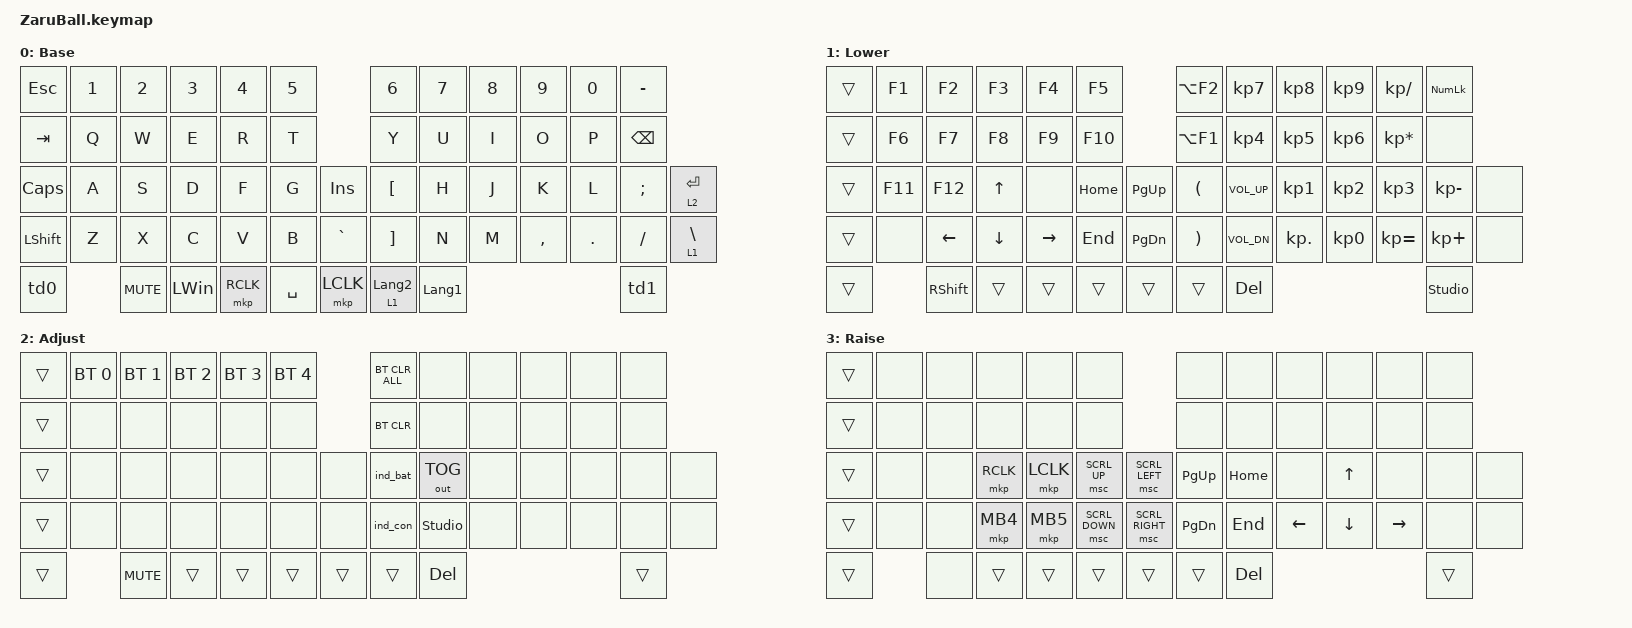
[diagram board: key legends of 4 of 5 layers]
#include <behaviors/rgbled_widget.dtsi>
#include <input/processors.dtsi>
#include <dt-bindings/zmk/input_transform.h>
#include <behaviors.dtsi>
#include <dt-bindings/zmk/bt.h>
#include <dt-bindings/zmk/keys.h>
#include <dt-bindings/zmk/outputs.h>
#include <dt-bindings/zmk/pointing.h>

#define BASE 0
#define LOWER 1
#define RAISE 2
#define ADJUST 3
#define MOUSE 4
#define SCROLL 1
#define JP_DQUOTE       AT                // "
#define JP_AMPERSAND    CARET             // &
#define JP_QUOTE        AMPERSAND         // '
#define JP_EQUAL        UNDER             // =
#define JP_CARET        EQUAL             // ^
#define JP_YEN          0x89              // ¥
#define JP_PLUS         COLON             // +
#define JP_TILDE        PLUS              // ~
#define JP_PIPE         LS(0x89)          // |
#define JP_AT           LEFT_BRACKET      // @
#define JP_COLON        SINGLE_QUOTE      // :
#define JP_ASTERISK     DOUBLE_QUOTES     // *
#define JP_BACKQUOTE    LEFT_BRACE        // `
#define JP_UNDERSCORE   LS(0x87)          // _
#define JP_LBRACKET     RIGHT_BRACKET     // [
#define JP_RBRACKET     BACKSLASH         // ]
#define JP_LPAREN       ASTERISK          // (
#define JP_RPAREN       LEFT_PARENTHESIS  // )
#define JP_LBRACE       RIGHT_BRACE       // {
#define JP_RBRACE       PIPE              // }
#define JP_KANA         LANGUAGE_1        // かな
#define JP_EISU         LANGUAGE_2        // 英数
#define JP_HANZEN       GRAVE             // 半角/全角
#define JP_BSLH  INT1         // (backslash)

// スクロール量の設定

#define ZMK_POINTING_DEFAULT_SCRL_VAL 100

// トラックボールの設定(AML, SCROLL)

&trackball_listener {
    input-processors = <
                        // トラックボールの向きの変更(ZaruBallv1とv2,v3ではセンサーの向きが異なるので調整してください。デフォルトではv2,v3用)
                         &zip_xy_transform (INPUT_TRANSFORM_XY_SWAP | INPUT_TRANSFORM_Y_INVERT | INPUT_TRANSFORM_X_INVERT)
                         &zip_temp_layer MOUSE 500 // 500ms stay at mouse layer
    >;

    scroller {
        layers = <SCROLL>;
        input-processors = <
                            // スクロールの向きの変更
                            &zip_xy_transform (INPUT_TRANSFORM_XY_SWAP | INPUT_TRANSFORM_X_INVERT)
                            &zip_xy_scaler 1 20 // スクロールの感度(default: x20)
                            &zip_xy_to_scroll_mapper
        >;
    };
};

/ {
    conditional_layers {
        compatible = "zmk,conditional-layers";

        tri_layer {
            if-layers = <1 3>;
            then-layer = <2>;
        };
    };
};

/ {
    behaviors {
        // スクロール用のbehaviorの設定

        scroll_down_up: behavior_sensor_rotate_mouse_wheel_down_up {
            compatible = "zmk,behavior-sensor-rotate";
            #sensor-binding-cells = <0>;
            bindings = <&msc SCRL_DOWN>, <&msc SCRL_UP>;

            tap-ms = <20>; // スクロールのタップ時間
        };

        td0: tap_dance_0 {
            compatible = "zmk,behavior-tap-dance";
            #binding-cells = <0>;
            tapping-term-ms = <200>;
            bindings = <&mt LALT LANG2>, <&mo 3>, <&mo 4>;
        };

        td1: tap_dance_1 {
            compatible = "zmk,behavior-tap-dance";
            #binding-cells = <0>;
            tapping-term-ms = <200>;
            bindings = <&mt RCTL LANG1>, <&mo 3>, <&mo 5>;
        };
    };
};

&sl { release-after-ms = <250>; }; // time needed for double click (for mkp_exit_AML)
/ {
    macros {
        // When in AML, move to default layer when key (except mouse button) pressed

        to_layer_0: to_layer_0 {
            compatible = "zmk,behavior-macro-one-param";
            #binding-cells = <1>;
            bindings = <&to 0 &macro_param_1to1 &kp MACRO_PLACEHOLDER>;
            label = "TO_layer_0";
        };

        // When LCLK pressed, exit AML (after 250ms cause by sticky layer)

        mkp_exit_AML: mkp_exit_AML {
            compatible = "zmk,behavior-macro-one-param";
            #binding-cells = <1>;
            bindings =
                <&macro_press>,
                <&macro_param_1to1 &mkp MACRO_PLACEHOLDER>,
                <&macro_pause_for_release>,
                <&macro_release>,
                <&macro_param_1to1 &mkp MACRO_PLACEHOLDER>,
                <&macro_tap>,
                <&sl 4>;

            label = "MKP_EXIT_AML";
        };

        // Support swapping into Scroll layer when AML is activated

        to_scroll_layer: to_scroll_layer {
            compatible = "zmk,behavior-macro";
            #binding-cells = <0>;
            bindings =
                <&to 1>,
                <&macro_press>,
                <&mo 1>,
                <&macro_pause_for_release>,
                <&macro_release>,
                <&mo 1>;
        };
    };
};

/ {
    keymap {
        compatible = "zmk,keymap";

        base_layer {
            display-name = "Base";
            sensor-bindings = <&scroll_down_up>;
            bindings = <
&kp ESC    &kp N1  &kp N2      &kp N3    &kp N4     &kp N5                &kp NUMBER_6      &kp N7          &kp N8  &kp N9     &kp N0   &kp MINUS
&kp TAB    &kp Q   &kp W       &kp E     &kp R      &kp T                 &kp Y             &kp U           &kp I   &kp O      &kp P    &kp BACKSPACE
&kp CAPS   &kp A   &kp S       &kp D     &kp F      &kp G      &kp INS    &kp LBKT          &kp H           &kp J   &kp K      &kp L    &kp SEMI       &lt 2 ENTER
&kp LSHFT  &kp Z   &kp X       &kp C     &kp V      &kp B      &kp GRAVE  &kp RBKT          &kp N           &kp M   &kp COMMA  &kp DOT  &kp FSLH       &lt 1 BACKSLASH
&td0               &kp C_MUTE  &kp LWIN  &mkp RCLK  &kp SPACE  &mkp LCLK  &lt 1 LANGUAGE_2  &kp LANGUAGE_1                              &td1
            >;
        };

        lower_layer {
            display-name = "Lower";
            sensor-bindings = <&inc_dec_kp RIGHT LEFT>;
            bindings = <
&trans  &kp F1   &kp F2     &kp F3    &kp F4     &kp F5               &kp LA(F2)  &kp KP_N7     &kp KP_N8   &kp KP_N9  &kp KP_SLASH     &kp KP_NUMLOCK
&trans  &kp F6   &kp F7     &kp F8    &kp F9     &kp F10              &kp LA(F1)  &kp KP_N4     &kp KP_N5   &kp KP_N6  &kp KP_MULTIPLY  &none
&trans  &kp F11  &kp F12    &kp UP    &none      &kp HOME  &kp PG_UP  &kp LPAR    &kp C_VOL_UP  &kp KP_N1   &kp KP_N2  &kp KP_N3        &kp KP_MINUS    &none
&trans  &none    &kp LEFT   &kp DOWN  &kp RIGHT  &kp END   &kp PG_DN  &kp RPAR    &kp C_VOL_DN  &kp KP_DOT  &kp KP_N0  &kp KP_EQUAL     &kp KP_PLUS     &none
&trans           &kp RSHFT  &trans    &trans     &trans    &trans     &trans      &kp DEL                                               &studio_unlock
            >;
        };

        adjust_layer {
            display-name = "Adjust";
            sensor-bindings = <&inc_dec_kp C_VOL_UP C_VOL_DN>;
            bindings = <
&trans  &bt BT_SEL 0  &bt BT_SEL 1  &bt BT_SEL 2  &bt BT_SEL 3  &bt BT_SEL 4          &bt BT_CLR_ALL  &none           &none  &none  &none  &none
&trans  &none         &none         &none         &none         &none                 &bt BT_CLR      &none           &none  &none  &none  &none
&trans  &none         &none         &none         &none         &none         &none   &ind_bat        &out OUT_TOG    &none  &none  &none  &none   &none
&trans  &none         &none         &none         &none         &none         &none   &ind_con        &studio_unlock  &none  &none  &none  &none   &none
&trans                &kp C_MUTE    &trans        &trans        &trans        &trans  &trans          &kp DEL                              &trans
            >;
        };

        raise_layer {
            display-name = "Raise";
            sensor-bindings = <&inc_dec_kp LA(F2) LA(F1)>;
            bindings = <
&trans  &none  &none  &none      &none      &none                            &none      &none     &none     &none     &none      &none
&trans  &none  &none  &none      &none      &none                            &none      &none     &none     &none     &none      &none
&trans  &none  &none  &mkp RCLK  &mkp LCLK  &msc SCRL_UP    &msc SCRL_LEFT   &kp PG_UP  &kp HOME  &none     &kp UP    &none      &none   &none
&trans  &none  &none  &mkp MB4   &mkp MB5   &msc SCRL_DOWN  &msc SCRL_RIGHT  &kp PG_DN  &kp END   &kp LEFT  &kp DOWN  &kp RIGHT  &none   &none
&trans         &none  &trans     &trans     &trans          &trans           &trans     &kp DEL                                  &trans
            >;
        };

        mouse_layer {
            display-name = "Mouse";
            sensor-bindings = <&scroll_down_up>;
            bindings = <
&to_layer_0 ESC             &to_layer_0 N1  &to_layer_0 N2  &to_layer_0 N3  &to_layer_0 N4      &to_layer_0 N5                   &to_layer_0 N6   &to_layer_0 N7  &to_layer_0 N8  &to_layer_0 N9  &to_layer_0 N0      &to_layer_0 MINUS
&to_layer_0 TAB             &to_layer_0 Q   &to_layer_0 W   &to_layer_0 E   &to_layer_0 R       &to_layer_0 T                    &to_layer_0 Y    &to_layer_0 U   &to_layer_0 I   &to_layer_0 O   &to_layer_0 P       &to_layer_0 EQUAL
&to_layer_0 CAPS            &to_layer_0 A   &mkp RCLK       &mkp MCLK       &mkp_exit_AML LCLK  &msc SCRL_UP    &msc SCRL_LEFT   &msc SCRL_LEFT   &msc SCRL_UP    &mkp LCLK       &mkp MCLK       &mkp RCLK           &to_layer_0 SINGLE_QUOTE  &to_layer_0 SEMICOLON
&to_layer_0 LSHIFT          &to_layer_0 Z   &to_layer_0 X   &mkp MB4        &mkp MB5            &msc SCRL_DOWN  &msc SCRL_RIGHT  &msc SCRL_RIGHT  &msc SCRL_DOWN  &mkp MB4        &mkp MB5        &to_layer_0 PERIOD  &to_layer_0 SLASH         &mt
&to_scroll_layer BACKSLASH                  &trans          &trans          &trans              &trans          &trans           &trans           &trans                                                              &trans
            >;
        };

        extra1 { status = "reserved"; };

        extra2 { status = "reserved"; };
    };
};
